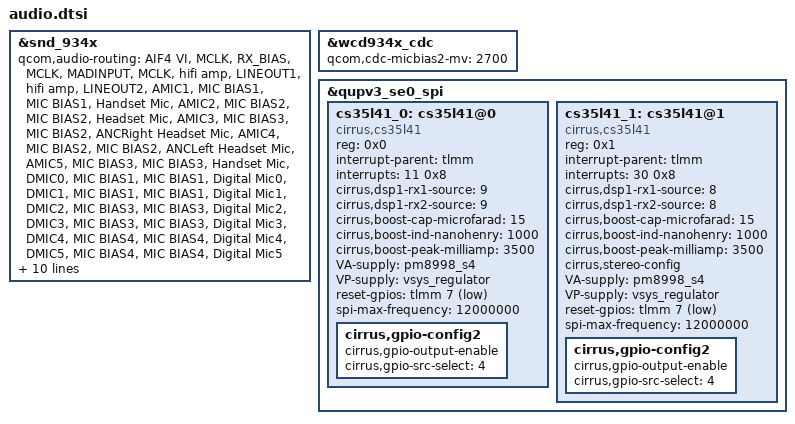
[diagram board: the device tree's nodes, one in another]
/*
 * Copyright (c) 2024, MeizuCustoms enthusiasts
 *
 * This program is free software; you can redistribute it and/or modify
 * it under the terms of the GNU General Public License version 2 and
 * only version 2 as published by the Free Software Foundation.
 *
 * This program is distributed in the hope that it will be useful,
 * but WITHOUT ANY WARRANTY; without even the implied warranty of
 * MERCHANTABILITY or FITNESS FOR A PARTICULAR PURPOSE.  See the
 * GNU General Public License for more details.
 */

&snd_934x {
	qcom,audio-routing =
		"AIF4 VI", "MCLK",
		"RX_BIAS", "MCLK",
		"MADINPUT", "MCLK",
		"hifi amp", "LINEOUT1",
		"hifi amp", "LINEOUT2",
		"AMIC1", "MIC BIAS1",
		"MIC BIAS1", "Handset Mic",
		"AMIC2", "MIC BIAS2",
		"MIC BIAS2", "Headset Mic",
		"AMIC3", "MIC BIAS3",
		"MIC BIAS2", "ANCRight Headset Mic",
		"AMIC4", "MIC BIAS2",
		"MIC BIAS2", "ANCLeft Headset Mic",
		"AMIC5", "MIC BIAS3",
		"MIC BIAS3", "Handset Mic",
		"DMIC0", "MIC BIAS1",
		"MIC BIAS1", "Digital Mic0",
		"DMIC1", "MIC BIAS1",
		"MIC BIAS1", "Digital Mic1",
		"DMIC2", "MIC BIAS3",
		"MIC BIAS3", "Digital Mic2",
		"DMIC3", "MIC BIAS3",
		"MIC BIAS3", "Digital Mic3",
		"DMIC4", "MIC BIAS4",
		"MIC BIAS4", "Digital Mic4",
		"DMIC5", "MIC BIAS4",
		"MIC BIAS4", "Digital Mic5";

    pinctrl-names = 
		"aud_active", "aud_sleep", 
		"quat-mi2s-sleep", "quat-mi2s-active", 
		"quat-mi2s-sleep-b2", "quat-mi2s-active-b2";
	pinctrl-2 = <&quat_mi2s_lines_sleep &quat_mi2s_sd2_sleep>;
	pinctrl-3 = <&quat_mi2s_lines_active &quat_mi2s_sd2_active>;
	pinctrl-4 = <&quat_mi2s_lines_sleep>;
	pinctrl-5 = <&quat_mi2s_lines_active>;

	qcom,msm-mbhc-hs-mic-max-threshold-mv = <2550>;
	qcom,msm-mbhc-hs-mic-min-threshold-mv = <75>;
	qcom,msm-mbhc-usbc-audio-supported;

    qcom,wsa-max-devs = <0>;
    
    /delete-property/ qcom,usbc-analog-en2-gpio;
};

&wcd934x_cdc {
	qcom,cdc-micbias2-mv = <2700>;
};

&qupv3_se0_spi {
	status = "ok";

	cs35l41_0: cs35l41@0 {
		#sound-dai-cells = <0x01>;
		compatible = "cirrus,cs35l41";
		reg = <0x0>;

		interrupt-parent = <&tlmm>;
		interrupts = <11 0x8>;

		cirrus,dsp1-rx1-source = <9>; // CS35L41_INPUT_SRC_ASPRX2
		cirrus,dsp1-rx2-source = <9>; // CS35L41_INPUT_SRC_ASPRX2
		cirrus,boost-cap-microfarad = <15>;
		cirrus,boost-ind-nanohenry = <1000>;
		cirrus,boost-peak-milliamp = <3500>;

		VA-supply = <&pm8998_s4>;
		VP-supply = <&vsys_regulator>;

		reset-gpios = <&tlmm 7 0x1>;
		spi-max-frequency = <12000000>;

		cirrus,gpio-config2 {
			cirrus,gpio-output-enable;
			cirrus,gpio-src-select = <4>;
		};
	};

	cs35l41_1: cs35l41@1 {
		#sound-dai-cells = <0x01>;
		compatible = "cirrus,cs35l41";
		reg = <0x1>;

		interrupt-parent = <&tlmm>;
		interrupts = <30 0x8>;

		cirrus,dsp1-rx1-source = <8>; // CS35L41_INPUT_SRC_ASPRX1
		cirrus,dsp1-rx2-source = <8>; // CS35L41_INPUT_SRC_ASPRX1
		cirrus,boost-cap-microfarad = <15>;
		cirrus,boost-ind-nanohenry = <1000>;
		cirrus,boost-peak-milliamp = <3500>;
		cirrus,stereo-config;

		VA-supply = <&pm8998_s4>;
		VP-supply = <&vsys_regulator>;

		reset-gpios = <&tlmm 7 0x1>;
		spi-max-frequency = <12000000>;
		
		cirrus,gpio-config2 {
			cirrus,gpio-output-enable;
			cirrus,gpio-src-select = <4>;
		};
	};
};
